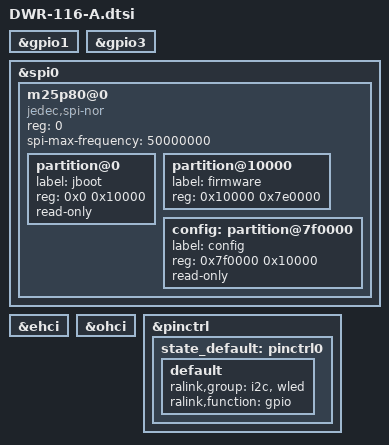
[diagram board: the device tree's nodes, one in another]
#include "mt7620n.dtsi"

#include <dt-bindings/gpio/gpio.h>
#include <dt-bindings/input/input.h>

&gpio1 {
	status = "okay";
};

&gpio3 {
	status = "okay";
};

&spi0 {
	status = "okay";

	m25p80@0 {
		#address-cells = <1>;
		#size-cells = <1>;
		compatible = "jedec,spi-nor";
		reg = <0>;
		spi-max-frequency = <50000000>;

		partition@0 {
			label = "jboot";
			reg = <0x0 0x10000>;
			read-only;
		};
		
		partition@10000 {
			label = "firmware";
			reg = <0x10000 0x7e0000>;
		};

		config: partition@7f0000 {
			label = "config";
			reg = <0x7f0000 0x10000>;
			read-only;
		};
	};
};

&ehci {
	status = "okay";
};

&ohci {
	status = "okay";
};

&pinctrl {
	state_default: pinctrl0 {
		default {
			ralink,group = "i2c", "wled";
			ralink,function = "gpio";
		};
	};
};


